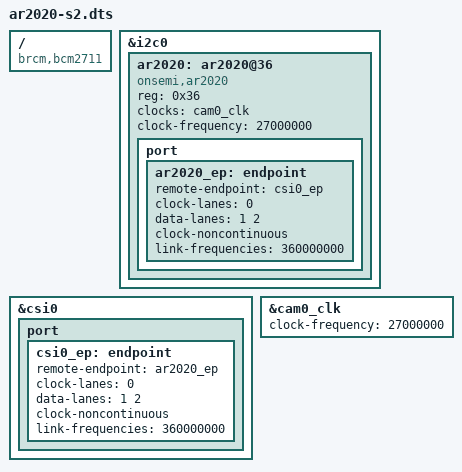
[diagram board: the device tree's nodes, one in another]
/dts-v1/;
/plugin/;

/ {
    compatible = "brcm,bcm2711";

    fragment@0 {
        target = <&i2c0>;
        __overlay__ {
            #address-cells = <1>;
            #size-cells = <0>;
            status = "okay";

            ar2020: ar2020@36 {
                compatible = "onsemi,ar2020";
                reg = <0x36>;
                status = "okay";

                clocks = <&cam0_clk>;
                clock-names = "xvclk";
		clock-frequency = <27000000>;
                
		port {
                    ar2020_ep: endpoint {
                        remote-endpoint = <&csi0_ep>;
                        clock-lanes = <0>;
                        data-lanes = <1 2>;
                        clock-noncontinuous;
                        link-frequencies = /bits/ 64 <360000000>;
                    };
                };
            };
        };
    };

    fragment@1 {
        target = <&csi0>;
        __overlay__ {
            status = "okay";
            port {
                csi0_ep: endpoint {
                    remote-endpoint = <&ar2020_ep>;
                    clock-lanes = <0>;
                    data-lanes = <1 2>;
                    clock-noncontinuous;
                    link-frequencies = /bits/ 64 <360000000>;
                };
            };
        };
    };

    fragment@2 {
        target = <&cam0_clk>;
        __overlay__ {
            clock-frequency = <27000000>;
            status = "okay";
        };
    };
};
